# ESP32C3 register map
File version: 1.0
CPU: RISC-V RV32IMC single-core 1, little endian, no MPU, FPU, 3 interrupt priority bits
Registers are 32-bit, read-write, reset 0x0 unless marked. A register's access mark holds for its fields unless they carry their own. Offsets are from the block's base; [hi:lo] are bit positions; {n}, {i} and the like mark numbered series.

## SPI
Base 0x00000000
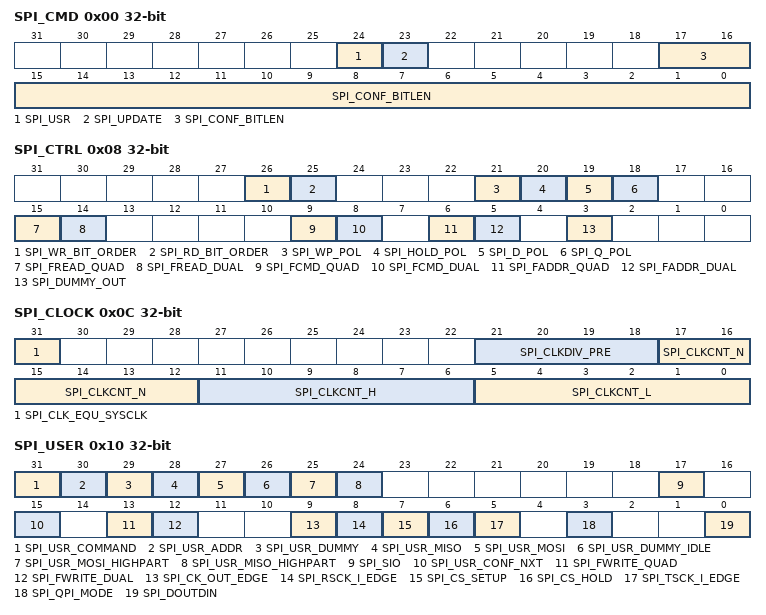
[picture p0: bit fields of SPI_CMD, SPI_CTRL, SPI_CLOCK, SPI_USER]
0x00 SPI_CMD access per field
  [24] SPI_USR rw, [23] SPI_UPDATE wo, [17:0] SPI_CONF_BITLEN rw
0x04 SPI_ADDR
  [31:0] SPI_USR_ADDR_VALUE
0x08 SPI_CTRL
  [26] SPI_WR_BIT_ORDER, [25] SPI_RD_BIT_ORDER, [21] SPI_WP_POL, [20] SPI_HOLD_POL, [19] SPI_D_POL, [18] SPI_Q_POL, [15] SPI_FREAD_QUAD, [14] SPI_FREAD_DUAL, [9] SPI_FCMD_QUAD, [8] SPI_FCMD_DUAL, [6] SPI_FADDR_QUAD, [5] SPI_FADDR_DUAL, [3] SPI_DUMMY_OUT
0x0C SPI_CLOCK
  [31] SPI_CLK_EQU_SYSCLK, [21:18] SPI_CLKDIV_PRE, [17:12] SPI_CLKCNT_N, [11:6] SPI_CLKCNT_H, [5:0] SPI_CLKCNT_L
0x10 SPI_USER
  [31] SPI_USR_COMMAND, [30] SPI_USR_ADDR, [29] SPI_USR_DUMMY, [28] SPI_USR_MISO, [27] SPI_USR_MOSI, [26] SPI_USR_DUMMY_IDLE, [25] SPI_USR_MOSI_HIGHPART, [24] SPI_USR_MISO_HIGHPART, [17] SPI_SIO, [15] SPI_USR_CONF_NXT, [13] SPI_FWRITE_QUAD, [12] SPI_FWRITE_DUAL, [9] SPI_CK_OUT_EDGE, [8] SPI_RSCK_I_EDGE, [7] SPI_CS_SETUP, [6] SPI_CS_HOLD, [5] SPI_TSCK_I_EDGE, [3] SPI_QPI_MODE, [0] SPI_DOUTDIN
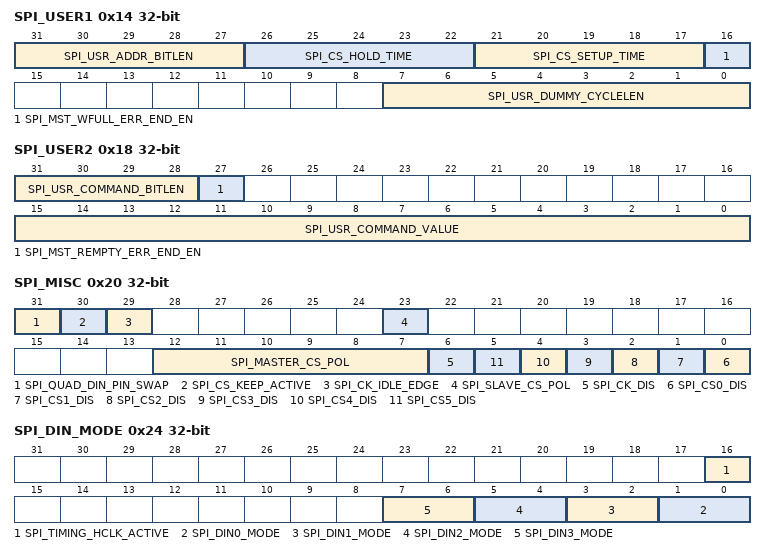
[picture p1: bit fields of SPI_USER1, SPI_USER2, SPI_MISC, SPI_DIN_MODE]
0x14 SPI_USER1
  [31:27] SPI_USR_ADDR_BITLEN, [26:22] SPI_CS_HOLD_TIME, [21:17] SPI_CS_SETUP_TIME, [16] SPI_MST_WFULL_ERR_END_EN, [7:0] SPI_USR_DUMMY_CYCLELEN
0x18 SPI_USER2
  [31:28] SPI_USR_COMMAND_BITLEN, [27] SPI_MST_REMPTY_ERR_END_EN, [15:0] SPI_USR_COMMAND_VALUE
0x1C SPI_MS_DLEN
  [17:0] SPI_MS_DATA_BITLEN
0x20 SPI_MISC
  [31] SPI_QUAD_DIN_PIN_SWAP, [30] SPI_CS_KEEP_ACTIVE, [29] SPI_CK_IDLE_EDGE, [23] SPI_SLAVE_CS_POL, [12:7] SPI_MASTER_CS_POL, [6] SPI_CK_DIS, [n] SPI_CS{n}_DIS (n=0..5)
0x24 SPI_DIN_MODE
  [16] SPI_TIMING_HCLK_ACTIVE, [2n+1:2n] SPI_DIN{n}_MODE (n=0..3)
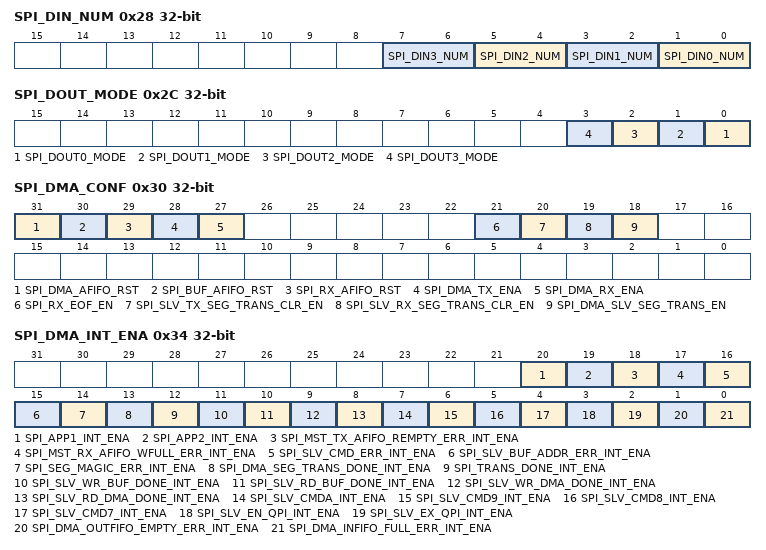
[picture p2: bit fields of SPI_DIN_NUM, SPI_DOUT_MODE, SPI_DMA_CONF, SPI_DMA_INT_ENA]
0x28 SPI_DIN_NUM
  [2n+1:2n] SPI_DIN{n}_NUM (n=0..3)
0x2C SPI_DOUT_MODE
  [n] SPI_DOUT{n}_MODE (n=0..3)
0x30 SPI_DMA_CONF access per field
  [31] SPI_DMA_AFIFO_RST wo, [30] SPI_BUF_AFIFO_RST wo, [29] SPI_RX_AFIFO_RST wo, [28] SPI_DMA_TX_ENA rw, [27] SPI_DMA_RX_ENA rw, [21] SPI_RX_EOF_EN rw, [20] SPI_SLV_TX_SEG_TRANS_CLR_EN rw, [19] SPI_SLV_RX_SEG_TRANS_CLR_EN rw, [18] SPI_DMA_SLV_SEG_TRANS_EN rw
0x34 SPI_DMA_INT_ENA
  [20] SPI_APP1_INT_ENA, [19] SPI_APP2_INT_ENA, [18] SPI_MST_TX_AFIFO_REMPTY_ERR_INT_ENA, [17] SPI_MST_RX_AFIFO_WFULL_ERR_INT_ENA, [16] SPI_SLV_CMD_ERR_INT_ENA, [15] SPI_SLV_BUF_ADDR_ERR_INT_ENA, [14] SPI_SEG_MAGIC_ERR_INT_ENA, [13] SPI_DMA_SEG_TRANS_DONE_INT_ENA, [12] SPI_TRANS_DONE_INT_ENA, [11] SPI_SLV_WR_BUF_DONE_INT_ENA, [10] SPI_SLV_RD_BUF_DONE_INT_ENA, [9] SPI_SLV_WR_DMA_DONE_INT_ENA, [8] SPI_SLV_RD_DMA_DONE_INT_ENA, [7] SPI_SLV_CMDA_INT_ENA, [6] SPI_SLV_CMD9_INT_ENA, [5] SPI_SLV_CMD8_INT_ENA, [4] SPI_SLV_CMD7_INT_ENA, [3] SPI_SLV_EN_QPI_INT_ENA, [2] SPI_SLV_EX_QPI_INT_ENA, [1] SPI_DMA_OUTFIFO_EMPTY_ERR_INT_ENA, [0] SPI_DMA_INFIFO_FULL_ERR_INT_ENA
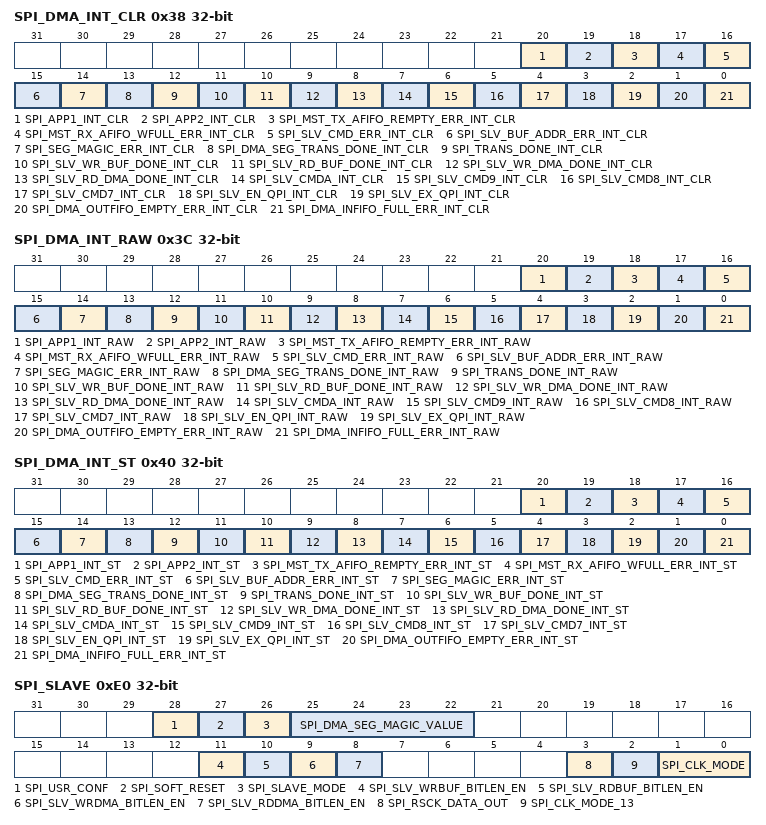
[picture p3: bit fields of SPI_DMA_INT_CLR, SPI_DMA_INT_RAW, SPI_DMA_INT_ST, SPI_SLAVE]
0x38 SPI_DMA_INT_CLR wo
  [20] SPI_APP1_INT_CLR, [19] SPI_APP2_INT_CLR, [18] SPI_MST_TX_AFIFO_REMPTY_ERR_INT_CLR, [17] SPI_MST_RX_AFIFO_WFULL_ERR_INT_CLR, [16] SPI_SLV_CMD_ERR_INT_CLR, [15] SPI_SLV_BUF_ADDR_ERR_INT_CLR, [14] SPI_SEG_MAGIC_ERR_INT_CLR, [13] SPI_DMA_SEG_TRANS_DONE_INT_CLR, [12] SPI_TRANS_DONE_INT_CLR, [11] SPI_SLV_WR_BUF_DONE_INT_CLR, [10] SPI_SLV_RD_BUF_DONE_INT_CLR, [9] SPI_SLV_WR_DMA_DONE_INT_CLR, [8] SPI_SLV_RD_DMA_DONE_INT_CLR, [7] SPI_SLV_CMDA_INT_CLR, [6] SPI_SLV_CMD9_INT_CLR, [5] SPI_SLV_CMD8_INT_CLR, [4] SPI_SLV_CMD7_INT_CLR, [3] SPI_SLV_EN_QPI_INT_CLR, [2] SPI_SLV_EX_QPI_INT_CLR, [1] SPI_DMA_OUTFIFO_EMPTY_ERR_INT_CLR, [0] SPI_DMA_INFIFO_FULL_ERR_INT_CLR
0x3C SPI_DMA_INT_RAW
  [20] SPI_APP1_INT_RAW, [19] SPI_APP2_INT_RAW, [18] SPI_MST_TX_AFIFO_REMPTY_ERR_INT_RAW, [17] SPI_MST_RX_AFIFO_WFULL_ERR_INT_RAW, [16] SPI_SLV_CMD_ERR_INT_RAW, [15] SPI_SLV_BUF_ADDR_ERR_INT_RAW, [14] SPI_SEG_MAGIC_ERR_INT_RAW, [13] SPI_DMA_SEG_TRANS_DONE_INT_RAW, [12] SPI_TRANS_DONE_INT_RAW, [11] SPI_SLV_WR_BUF_DONE_INT_RAW, [10] SPI_SLV_RD_BUF_DONE_INT_RAW, [9] SPI_SLV_WR_DMA_DONE_INT_RAW, [8] SPI_SLV_RD_DMA_DONE_INT_RAW, [7] SPI_SLV_CMDA_INT_RAW, [6] SPI_SLV_CMD9_INT_RAW, [5] SPI_SLV_CMD8_INT_RAW, [4] SPI_SLV_CMD7_INT_RAW, [3] SPI_SLV_EN_QPI_INT_RAW, [2] SPI_SLV_EX_QPI_INT_RAW, [1] SPI_DMA_OUTFIFO_EMPTY_ERR_INT_RAW, [0] SPI_DMA_INFIFO_FULL_ERR_INT_RAW
0x40 SPI_DMA_INT_ST ro
  [20] SPI_APP1_INT_ST, [19] SPI_APP2_INT_ST, [18] SPI_MST_TX_AFIFO_REMPTY_ERR_INT_ST, [17] SPI_MST_RX_AFIFO_WFULL_ERR_INT_ST, [16] SPI_SLV_CMD_ERR_INT_ST, [15] SPI_SLV_BUF_ADDR_ERR_INT_ST, [14] SPI_SEG_MAGIC_ERR_INT_ST, [13] SPI_DMA_SEG_TRANS_DONE_INT_ST, [12] SPI_TRANS_DONE_INT_ST, [11] SPI_SLV_WR_BUF_DONE_INT_ST, [10] SPI_SLV_RD_BUF_DONE_INT_ST, [9] SPI_SLV_WR_DMA_DONE_INT_ST, [8] SPI_SLV_RD_DMA_DONE_INT_ST, [7] SPI_SLV_CMDA_INT_ST, [6] SPI_SLV_CMD9_INT_ST, [5] SPI_SLV_CMD8_INT_ST, [4] SPI_SLV_CMD7_INT_ST, [3] SPI_SLV_EN_QPI_INT_ST, [2] SPI_SLV_EX_QPI_INT_ST, [1] SPI_DMA_OUTFIFO_EMPTY_ERR_INT_ST, [0] SPI_DMA_INFIFO_FULL_ERR_INT_ST
{0x98+4i} SPI_W{i} (i=0..15)
  [31:0] SPI_BUF{i}
0xE0 SPI_SLAVE access per field
  [28] SPI_USR_CONF rw, [27] SPI_SOFT_RESET wo, [26] SPI_SLAVE_MODE rw, [25:22] SPI_DMA_SEG_MAGIC_VALUE rw, [11] SPI_SLV_WRBUF_BITLEN_EN rw, [10] SPI_SLV_RDBUF_BITLEN_EN rw, [9] SPI_SLV_WRDMA_BITLEN_EN rw, [8] SPI_SLV_RDDMA_BITLEN_EN rw, [3] SPI_RSCK_DATA_OUT rw, [2] SPI_CLK_MODE_13 rw, [1:0] SPI_CLK_MODE rw
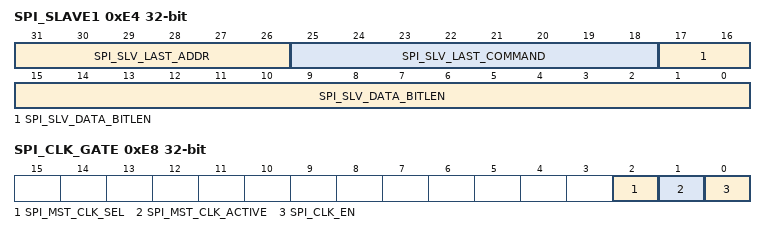
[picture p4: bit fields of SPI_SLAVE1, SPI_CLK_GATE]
0xE4 SPI_SLAVE1
  [31:26] SPI_SLV_LAST_ADDR, [25:18] SPI_SLV_LAST_COMMAND, [17:0] SPI_SLV_DATA_BITLEN
0xE8 SPI_CLK_GATE
  [2] SPI_MST_CLK_SEL, [1] SPI_MST_CLK_ACTIVE, [0] SPI_CLK_EN
0xF0 SPI_DATE
  [27:0] SPI_DATE
